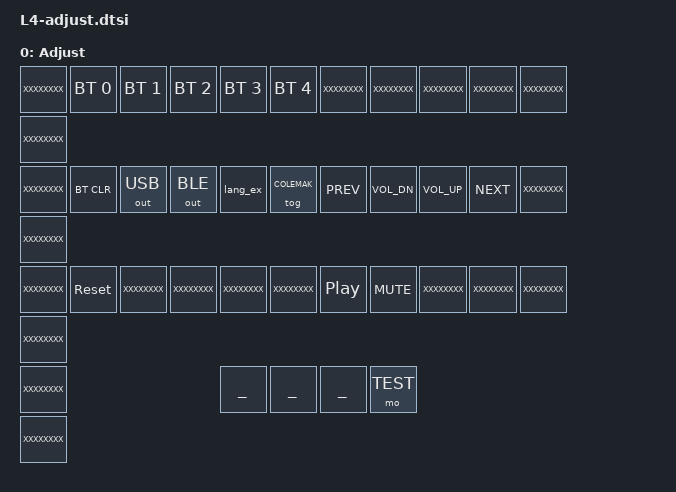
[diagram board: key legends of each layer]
/**
 *
 */

/ {
  keymap {
    compatible = "zmk,keymap";

	adjust_layer {
		label = "Adjust";
   		bindings = <
//					╭───────────────┬───────────────┬───────────────┬───────────────┬───────────────╮   ╭───────────────┬───────────────┬───────────────┬───────────────┬───────────────╮
//  0               	1               2               3               4               5                   6               7               8               9               10
	XXXXXXXX			&bt BT_SEL 0    &bt BT_SEL 1    &bt BT_SEL 2    &bt BT_SEL 3    &bt BT_SEL 4		XXXXXXXX        XXXXXXXX     	XXXXXXXX		XXXXXXXX		XXXXXXXX
	XXXXXXXX	//	├───────────────┼───────────────┼───────────────┼───────────────┼───────────────┤   ├───────────────├───────────────┼───────────────┼───────────────┼───────────────┤
//  12					13              14              15              16              17                  18              19              20              21              22
	XXXXXXXX			&bt BT_CLR		&out OUT_USB	&out OUT_BLE	&lang_ex		&tog COLEMAK		&kp C_PREV		&kp C_VOL_DN	&kp C_VOL_UP	&kp C_NEXT		XXXXXXXX
	XXXXXXXX	//	├───────────────┼───────────────┼───────────────┼───────────────┼───────────────┤   ├───────────────├───────────────┼───────────────┼───────────────┼───────────────┤
//  24					25              26              27              28              29                  30              31              32              33              34
	XXXXXXXX			&sys_reset		XXXXXXXX		XXXXXXXX        XXXXXXXX		XXXXXXXX			&kp C_PP		&kp C_MUTE		XXXXXXXX		XXXXXXXX        XXXXXXXX
	XXXXXXXX	//	╰───────────────┴───────────────┼───────────────┼───────────────┼───────────────┤   ├───────────────├───────────────┼───────────────┼───────────────┴───────────────╯
//	36              													37              38                  39              40
	XXXXXXXX       														________		________			________		&mo TEST
//                                                                  ╰───────────────┴───────────────╯   ╰───────────────┴───────────────╯
	XXXXXXXX
			>;
		};
	};
};
